# N32F030 register map
File version: 1.0
Registers are 32-bit, read-write, reset 0x0 unless marked. A register's access mark holds for its fields unless they carry their own. Offsets are from the block's base; [hi:lo] are bit positions.

## SYS — SYS Register Map
Base 0x50000000
0x00 SYS_PDID ro reset not defined — Part Device Identification Number Register
  [31:0] PDID — Part Device Identification Number (Read Only). This register reflects device part number code. Software can read this register to identify which device is used.
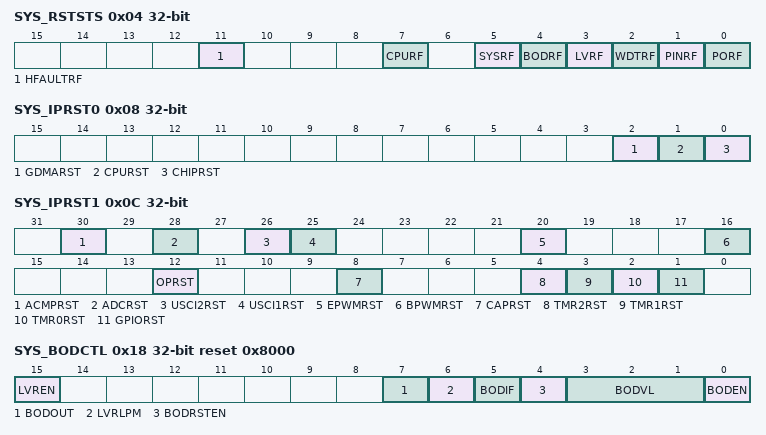
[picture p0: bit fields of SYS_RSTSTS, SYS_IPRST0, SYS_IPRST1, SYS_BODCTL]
0x04 SYS_RSTSTS (reset mask 0xFFFFFF00) — System Reset Status Register
  [11] HFAULTRF — Hard Fault Reset Flag. Note: Write 1 to clear this bit to 0.
    0=No reset from Hardfault; 1=The Cortex-M0 Core and FMC are reset by software setting HARDFAULTRST to 1
  [7] CPURF — CPU Reset Flag. The CPU reset flag is set by hardware if software writes CPURST (SYS_IPRST0[1]) 1 to reset Cortex-M0 Core and Flash Memory Controller (FMC). Note: Write 1 to clear this bit to 0.
    0=No reset from CPU; 1=The Cortex-M0 Core and FMC are reset by software setting CPURST to 1
  [5] SYSRF — System Reset Flag. The system reset flag is set by the 'Reset Signal' from the Cortex-M0 Core to indicate the previous reset source. Note: Write 1 to clear this bit to 0.
    0=No reset from Cortex-M0; 1=The Cortex-M0 had issued the reset signal to reset the system by writing 1 to the bit SYSRESETREQ(AIRCR[2], Application Interrupt and Reset Control Register, address = 0xE000ED0C) in system control registers of Cortex-M0 core
  [4] BODRF — BOD Reset Flag. The BOD reset flag is set by the 'Reset Signal' from the Brown-Out Detector to indicate the previous reset source. Note: Write 1 to clear this bit to 0.
    0=No reset from BOD; 1=The BOD had issued the reset signal to reset the system
  [3] LVRF — LVR Reset Flag. The LVR reset flag is set by the 'Reset Signal' from the Low Voltage Reset Controller to indicate the previous reset source. Note: Write 1 to clear this bit to 0.
    0=No reset from LVR; 1=LVR controller had issued the reset signal to reset the system
  [2] WDTRF — WDT Reset Flag. The WDT reset flag is set by the 'Reset Signal' from the Watchdog Timer or Window Watchdog Timer to indicate the previous reset source. Note1: Write 1 to clear this bit to 0. Note2: Watchdog Timer register RSTF(WDT_CTL[2]) bit is set if the system has been reset by WDT time-out reset. Window Watchdog Timer register WWDTRF(WWDT_STATUS[1]) bit is set if the system has been reset by WWDT time-out reset.
    0=No reset from watchdog timer or window watchdog timer; 1=The watchdog timer or window watchdog timer had issued the reset signal to reset the system
  [1] PINRF — NRESET Pin Reset Flag. The nRESET pin reset flag is set by the 'Reset Signal' from the nRESET Pin to indicate the previous reset source. Note: Write 1 to clear this bit to 0.
    0=No reset from nRESET pin; 1=Pin nRESET had issued the reset signal to reset the system
  [0] PORF — POR Reset Flag. The POR reset flag is set by the 'Reset Signal' from the Power-on Reset (POR) Controller or bit CHIPRST (SYS_IPRST0[0]) to indicate the previous reset source. Note: Write 1 to clear this bit to 0.
    0=No reset from POR or CHIPRST; 1=Power-on Reset (POR) or CHIPRST had issued the reset signal to reset the system
0x08 SYS_IPRST0 — Peripheral Reset Control Register 0
  [2] GDMARST — GDMA One-shot Reset (Write Protect). Setting this bit will only reset the GDMA, and this bit will automatically return to 0 after the 2 clock cycles. Note: This bit is write protected. Refer to the SYS_REGLCTL register.
    0=GDMA normal operation; 1=GDMA one-shot reset
  [1] CPURST — Processor Core One-shot Reset (Write Protect). Setting this bit will only reset the processor core and Flash Memory Controller(FMC), and this bit will automatically return to 0 after the 2 clock cycles. Note: This bit is write protected. Refer to the SYS_REGLCTL register.
    0=Processor core normal operation; 1=Processor core one-shot reset
  [0] CHIPRST — Chip One-shot Reset (Write Protect). Setting this bit will reset the whole chip, including Processor core and all peripherals, and this bit will automatically return to 0 after the 2 clock cycles. The CHIPRST is same as the POR reset, all the chip controllers is reset and the chip setting from flash are also reload. About the difference between CHIPRST and SYSRESETREQ(AIRCR[2]), please refer to section 6.2.2. Note: This bit is write protected. Refer to the SYS_REGLCTL register.
    0=Chip normal operation; 1=Chip one-shot reset
0x0C SYS_IPRST1 — Peripheral Reset Control Register 1
  [30] ACMPRST — ACMP Controller Reset
    0=ACMP controller normal operation; 1=ACMP controller reset
  [28] ADCRST — ADC Controller Reset
    0=ADC controller normal operation; 1=ADC controller reset
  [26] USCI2RST — USCI2 Controller Reset
    0=USCI2 controller normal operation; 1=USCI2 controller reset
  [25] USCI1RST — USCI1 Controller Reset
    0=USCI1 controller normal operation; 1=USCI1 controller reset
  [20] EPWMRST — Enhanced PWM Controller Reset
    0=EPWM controller normal operation; 1=EPWM controller reset
  [16] BPWMRST — Basic PWM Controller Reset
    0=BPWM controller normal operation; 1=BPWM controller reset
  [12] OPRST — OP Controller Reset
    0=OP controller normal operation; 1=OP controller reset
  [8] CAPRST — CAP Controller Reset
    0=CAP controller normal operation; 1=CAP controller reset
  [4] TMR2RST — Timer2 Controller Reset
    0=Timer2 controller normal operation; 1=Timer2 controller reset
  [3] TMR1RST — Timer1 Controller Reset
    0=Timer1 controller normal operation; 1=Timer1 controller reset
  [2] TMR0RST — Timer0 Controller Reset
    0=Timer0 controller normal operation; 1=Timer0 controller reset
  [1] GPIORST — GPIO Controller Reset
    0=GPIO controller normal operation; 1=GPIO controller reset
0x10 SYS_WAIT reset 0x1 — HCLK Wait State Cycle Control Register
  [0] HCLKWS — HCLK Wait State Cycle Control Bit. This bit is used to enable/disable HCLK wait state when access Flash. Note: When HCLK frequency is faster than 48M(60)Hz, insert one wait state is necessary.
    0=No wait state; 1=One wait state inserted when CPU access Flash
0x18 SYS_BODCTL reset 0x8000 (reset mask 0xFFFFFF00) — Brown-out Detector Control Register
  [15] LVREN — Low Voltage Reset Enable Control (Write Protect). The LVR function resets the chip when the input power voltage is lower than LVR circuit setting. LVR function is enabled by default. Note: This bit is write protected. Refer to the SYS_REGLCTL register.
    0=Low Voltage Reset function Disabled; 1=Low Voltage Reset function Enabled
  [7] BODOUT — Brown-out Detector Output Status
    0=Brown-out Detector output status is 0. It means the detected voltage is higher than BODVL setting or BODEN is 0; 1=Brown-out Detector output status is 1. It means the detected voltage is lower than BODVL setting. If the BODEN is 0, BOD function disabled , this bit always responds 0000
  [6] LVRLPM — Low Voltage Reset Low Power Mode (Write Protect). Note1: The LVR consumes about 100uA in normal mode, the low power mode can reduce the current to about 1/10 but slow the LVR response. Note2: This bit is write protected. Refer to the SYS_REGLCTL register.
    0=LVR operate in normal mode (default); 1=LVR Low Power mode Enabled
  [5] BODIF — Brown-out Detector Interrupt Flag. Note: Write 1 to clear this bit to 0.
    0=Brown-out Detector does not detect any voltage draft at VDD down through or up through the voltage of BODVL setting; 1=When Brown-out Detector detects the VDD is dropped down through the voltage of BODVL setting or the VDD is raised up through the voltage of BODVL setting, this bit is set to 1 and the brown-out interrupt is requested if brown-out interrupt is enabled
  [4] BODRSTEN — Brown-out Reset Enable Control (Write Protect). The default value is set by flash controller user configuration register CBORST(CONFIG0[19]) bit . Note1: While the Brown-out Detector function is enabled (BODEN high) and BOD reset function is enabled (BODRSTEN high), BOD will assert a signal to reset chip when the detected voltage is lower than the threshold (BODOUT high). While the BOD function is enabled (BODEN high) and BOD interrupt function is enabled (BODRSTEN low), BOD will assert an interrupt if BODOUT is high. BOD interrupt will keep till to the BODEN set to 0. BOD interrupt can be blocked by disabling the NVIC BOD interrupt or disabling BOD function (set BODEN low). BOD will wake CPU up when BODOUT is high in power-down mode. Note2: This bit is write protected. Refer to the SYS_REGLCTL register.
    0=Brown-out 'INTERRUPT' function Enabled; 1=Brown-out 'RESET' function Enabled
  [3:1] BODVL — Brown-out Detector Threshold Voltage Selection (Write Protect). The default value is set by flash controller user configuration register CBOV (CONFIG0 [15:13]). Note: This bit is write protected. Refer to the SYS_REGLCTL register.
    0=Brown-Out Detector threshold voltage is 2.0V; 1=Brown-Out Detector threshold voltage is 2.2V; 2=Brown-Out Detector threshold voltage is 2.4V; 3=Brown-Out Detector threshold voltage is 2.7V; 4=Brown-Out Detector threshold voltage is 3.0V; 5=Brown-Out Detector threshold voltage is 3.7V; 6=Brown-Out Detector threshold voltage is 4.0V; 7=Brown-Out Detector threshold voltage is 4.3V
  [0] BODEN — Brown-out Detector Enable Control (Write Protect). The default value is set by flash controller user configuration register CBODEN (CONFIG0 [11]). Note: This bit is write protected. Refer to the SYS_REGLCTL register.
    0=Brown-out Detector function Disabled; 1=Brown-out Detector function Enabled
0x1C SYS_IVSCTL — Internal Voltage Source Control Register
  [0] VTEMPEN — Temperature Sensor Enable Control. This bit is used to enable/disable temperature sensor function. Note: After this bit is set to 1, the value of temperature sensor output can be obtained from A/D conversion result. Please refer to ADC function chapter for details.
    0=Temperature sensor function Disabled (default); 1=Temperature sensor function Enabled
0x24 SYS_PORCTL (reset mask 0xFFFFFF00) — Power-On-reset Controller Register
  [15:0] POROFF — Power-on Reset Enable Control (Write Protect). When powered on, the POR circuit generates a reset signal to reset the whole chip function, but noise on the power may cause the POR active again. User can disable internal POR circuit to avoid unpredictable noise to cause chip reset by writing 0x5AA5 to this field. The POR function will be active again when this field is set to another value or chip is reset by other reset source, including: nRESET, Watchdog, LVR reset, BOD reset, ICE reset command and the software-chip reset function. Note: This bit is write protected. Refer to the SYS_REGLCTL register.
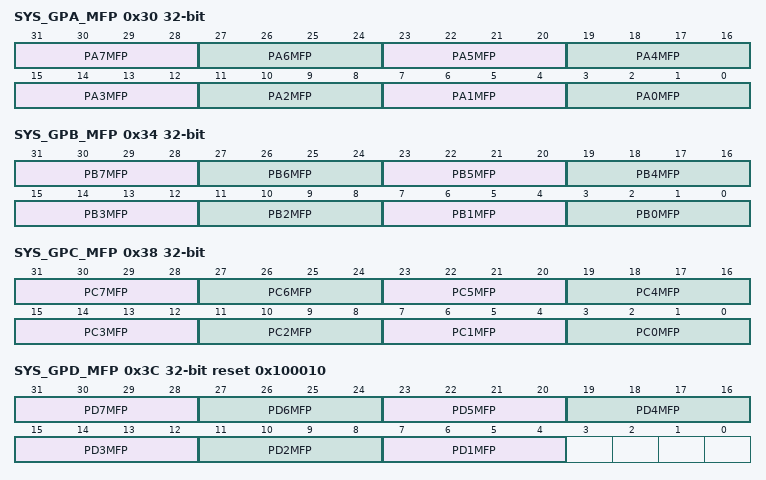
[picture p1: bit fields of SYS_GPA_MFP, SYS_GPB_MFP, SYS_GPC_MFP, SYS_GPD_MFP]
0x30 SYS_GPA_MFP — GPIOA Multiple Function Control Register
  [31:28] PA7MFP — PA.7 Multi-function Pin Selection
  [27:24] PA6MFP — PA.6 Multi-function Pin Selection
  [23:20] PA5MFP — PA.5 Multi-function Pin Selection
  [19:16] PA4MFP — PA.4 Multi-function Pin Selection
  [15:12] PA3MFP — PA.3 Multi-function Pin Selection
  [11:8] PA2MFP — PA.2 Multi-function Pin Selection
  [7:4] PA1MFP — PA.1 Multi-function Pin Selection
  [3:0] PA0MFP — PA.0 Multi-function Pin Selection
0x34 SYS_GPB_MFP — GPIOB Multiple Function Control Register
  [31:28] PB7MFP — PB.7 Multi-function Pin Selection
  [27:24] PB6MFP — PB.6 Multi-function Pin Selection
  [23:20] PB5MFP — PB.5 Multi-function Pin Selection
  [19:16] PB4MFP — PB.4 Multi-function Pin Selection
  [15:12] PB3MFP — PB.3 Multi-function Pin Selection
  [11:8] PB2MFP — PB.2 Multi-function Pin Selection
  [7:4] PB1MFP — PB.1 Multi-function Pin Selection
  [3:0] PB0MFP — PB.0 Multi-function Pin Selection
0x38 SYS_GPC_MFP — GPIOC Multiple Function Control Register
  [31:28] PC7MFP — PC.7 Multi-function Pin Selection
  [27:24] PC6MFP — PC.6 Multi-function Pin Selection
  [23:20] PC5MFP — PC.5 Multi-function Pin Selection
  [19:16] PC4MFP — PC.4 Multi-function Pin Selection
  [15:12] PC3MFP — PC.3 Multi-function Pin Selection
  [11:8] PC2MFP — PC.2 Multi-function Pin Selection
  [7:4] PC1MFP — PC.1 Multi-function Pin Selection
  [3:0] PC0MFP — PC.0 Multi-function Pin Selection
0x3C SYS_GPD_MFP reset 0x100010 — GPIOD Multiple Function Control Register
  [31:28] PD7MFP — PD.7 Multi-function Pin Selection
  [27:24] PD6MFP — PD.6 Multi-function Pin Selection
  [23:20] PD5MFP — PD.5 Multi-function Pin Selection
  [19:16] PD4MFP — PD.4 Multi-function Pin Selection
  [15:12] PD3MFP — PD.3 Multi-function Pin Selection
  [11:8] PD2MFP — PD.2 Multi-function Pin Selection
  [7:4] PD1MFP — PD.1 Multi-function Pin Selection
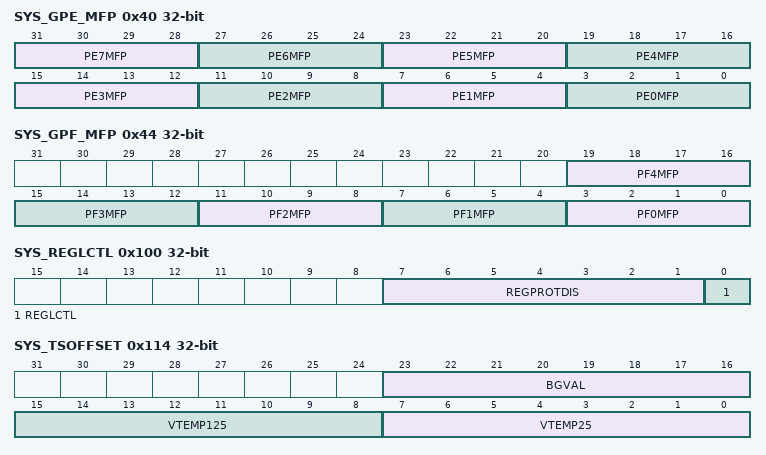
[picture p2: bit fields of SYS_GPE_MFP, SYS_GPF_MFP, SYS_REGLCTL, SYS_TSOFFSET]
0x40 SYS_GPE_MFP — GPIOE Multiple Function Control Register
  [31:28] PE7MFP — PE.7 Multi-function Pin Selection
  [27:24] PE6MFP — PE.6 Multi-function Pin Selection
  [23:20] PE5MFP — PE.5 Multi-function Pin Selection
  [19:16] PE4MFP — PE.4 Multi-function Pin Selection
  [15:12] PE3MFP — PE.3 Multi-function Pin Selection
  [11:8] PE2MFP — PE.2 Multi-function Pin Selection
  [7:4] PE1MFP — PE.1 Multi-function Pin Selection
  [3:0] PE0MFP — PE.0 Multi-function Pin Selection
0x44 SYS_GPF_MFP — GPIOF Multiple Function Control Register
  [19:16] PF4MFP — PF.4 Multi-function Pin Selection
  [15:12] PF3MFP — PF.3 Multi-function Pin Selection
  [11:8] PF2MFP — PF.2 Multi-function Pin Selection
  [7:4] PF1MFP — PF.1 Multi-function Pin Selection
  [3:0] PF0MFP — PF.0 Multi-function Pin Selection
0x100 SYS_REGLCTL — Register Write-protection Control Register
  [7:1] REGPROTDIS wo — Register Write-protection Code (Write Only). Some registers have write-protection function. Writing these registers have to disable the protected function by writing the sequence value 0x59, 0x16, 0x88 to this field. After this sequence is completed, the SYS_REGLCTL bit will be set to 1 and write-protection registers can be normal write.
  [0] REGLCTL ro — Register Lock Control Disable Index (Read Only) . The Protected registers are: SYS_IPRST0. SYS_IPRST0. SYS_BODCTL. LDOCR. SYS_PORCTL. CLK_PWRCTL. CLK_APBCLK bit[0]. CLK_CLKSEL0. CLK_CLKSEL1 bit[1:0]. NMI_SEL bit[8]. FMC_ISPCTL. FMC_ISPTRG. WDT_CTL. Note: The bits which are write-protected will be noted as' (Write Protect)' beside the description.
    0=Write-protection Enabled for writing protected registers. Any write to the protected register is ignored; 1=Write-protection Disabled for writing protected registers
0x114 SYS_TSOFFSET ro reset not defined — Temperature Sensor Offset Register
  [23:16] BGVAL — +896 . 5000
  [15:8] VTEMP125
  [7:0] VTEMP25
